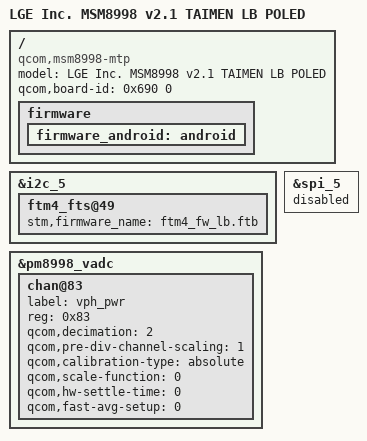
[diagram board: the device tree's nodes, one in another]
/* Copyright (c) 2017, The Linux Foundation. All rights reserved.
 *
 * This program is free software; you can redistribute it and/or modify
 * it under the terms of the GNU General Public License version 2 and
 * only version 2 as published by the Free Software Foundation.
 *
 * This program is distributed in the hope that it will be useful,
 * but WITHOUT ANY WARRANTY; without even the implied warranty of
 * MERCHANTABILITY or FITNESS FOR A PARTICULAR PURPOSE.  See the
 * GNU General Public License for more details.
 */

/dts-v1/;

/* WIP: Device tree overlay: SoC dtbo */
#include "../qcom/msm8998-v2.1.dtsi"
/ {
	compatible = "qcom,msm8998-mtp", "qcom,msm8998", "qcom,mtp";
	firmware {
		firmware_android: android {};
	};
};

/*
 * TODO: Device tree overlay:
 * below part is to be removed and the information will be
 * provided through DTB/DTBO partition dt_table_entry.
 */

/ {
	model = "LGE Inc. MSM8998 v2.1 TAIMEN LB POLED";
	qcom,board-id = <0x690 0>;
};

/* WIP: Device tree overlay: overlay dtbo */
#include "msm8998-taimen.dtsi"

&i2c_5 {
	status = "ok";
};

&pm8998_vadc {
	chan@83 {
		label = "vph_pwr";
		reg = <0x83>;
		qcom,decimation = <2>;
		qcom,pre-div-channel-scaling = <1>;
		qcom,calibration-type = "absolute";
		qcom,scale-function = <0>;
		qcom,hw-settle-time = <0>;
		qcom,fast-avg-setup = <0>;
	};
};

&spi_5 {
	status = "disabled";
};

&i2c_5 {
	ftm4_fts@49 {
		stm,firmware_name = "ftm4_fw_lb.ftb";
	};
};
